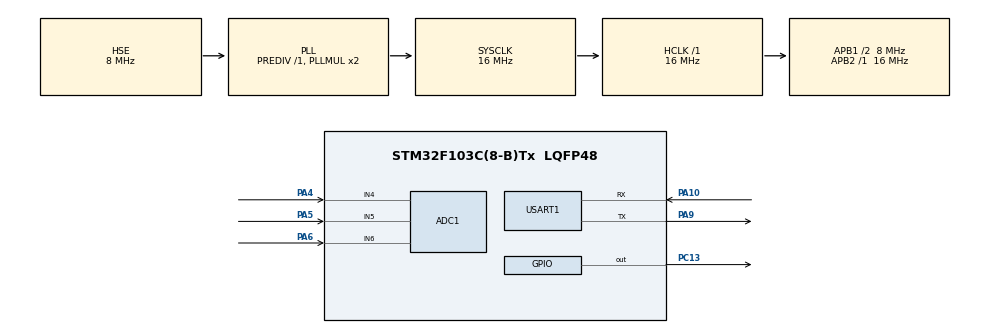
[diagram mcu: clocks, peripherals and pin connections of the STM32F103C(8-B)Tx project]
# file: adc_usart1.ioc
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ADC1.Channel-5\#ChannelRegularConversion=ADC_CHANNEL_4
ADC1.Channel-6\#ChannelRegularConversion=ADC_CHANNEL_5
ADC1.Channel-7\#ChannelRegularConversion=ADC_CHANNEL_6
ADC1.ContinuousConvMode=ENABLE
ADC1.NbrOfConversion=3
ADC1.NbrOfConversionFlag=1
ADC1.Rank-5\#ChannelRegularConversion=1
ADC1.Rank-6\#ChannelRegularConversion=2
ADC1.Rank-7\#ChannelRegularConversion=3
ADC1.SamplingTime-5\#ChannelRegularConversion=ADC_SAMPLETIME_239CYCLES_5
ADC1.SamplingTime-6\#ChannelRegularConversion=ADC_SAMPLETIME_239CYCLES_5
ADC1.SamplingTime-7\#ChannelRegularConversion=ADC_SAMPLETIME_239CYCLES_5
ADC1.master=1
Dma.ADC1.0.Direction=DMA_PERIPH_TO_MEMORY
Dma.ADC1.0.Instance=DMA1_Channel1
Dma.ADC1.0.MemDataAlignment=DMA_MDATAALIGN_WORD
Dma.ADC1.0.MemInc=DMA_MINC_ENABLE
Dma.ADC1.0.Mode=DMA_CIRCULAR
Dma.ADC1.0.PeriphDataAlignment=DMA_PDATAALIGN_WORD
Dma.ADC1.0.PeriphInc=DMA_PINC_DISABLE
Dma.ADC1.0.Priority=DMA_PRIORITY_LOW
Dma.Request0=ADC1
Mcu.Family=STM32F1
Mcu.Name=STM32F103C(8-B)Tx
Mcu.Package=LQFP48
NVIC.DMA1_Channel1_IRQn=true\:0\:0\:false\:false\:true\:false\:true
NVIC.PriorityGroup=NVIC_PRIORITYGROUP_4
PA10.Mode=Asynchronous
PA10.Signal=USART1_RX
PA13.Mode=Serial_Wire
PA13.Signal=SYS_JTMS-SWDIO
PA14.Mode=Serial_Wire
PA14.Signal=SYS_JTCK-SWCLK
PA4.Signal=ADCx_IN4
PA5.Signal=ADCx_IN5
PA6.Signal=ADCx_IN6
PA9.Mode=Asynchronous
PA9.Signal=USART1_TX
PC13-TAMPER-RTC.Signal=GPIO_Output
PD0-OSC_IN.Mode=HSE-External-Oscillator
PD0-OSC_IN.Signal=RCC_OSC_IN
PD1-OSC_OUT.Mode=HSE-External-Oscillator
PD1-OSC_OUT.Signal=RCC_OSC_OUT
ProjectManager.HeapSize=0x200
ProjectManager.StackSize=0x400
ProjectManager.TargetToolchain=STM32CubeIDE
RCC.AHBFreq_Value=16000000
RCC.APB1CLKDivider=RCC_HCLK_DIV2
RCC.APB1Freq_Value=8000000
RCC.APB1TimFreq_Value=16000000
RCC.APB2Freq_Value=16000000
RCC.APB2TimFreq_Value=16000000
RCC.HCLKFreq_Value=16000000
RCC.PLLSourceVirtual=RCC_PLLSOURCE_HSE
RCC.SYSCLKFreq_VALUE=16000000
RCC.SYSCLKSource=RCC_SYSCLKSOURCE_PLLCLK
RCC.USBFreq_Value=16000000
SH.ADCx_IN4.0=ADC1_IN4,IN4
SH.ADCx_IN5.0=ADC1_IN5,IN5
SH.ADCx_IN6.0=ADC1_IN6,IN6
USART1.VirtualMode=VM_ASYNC
board=custom

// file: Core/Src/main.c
/* USER CODE BEGIN Header */
/**
  ******************************************************************************
  * @file           : main.c
  * @brief          : Main program body
  ******************************************************************************
  * @attention
  *
  * <h2><center>&copy; Copyright (c) 2020 STMicroelectronics.
  * All rights reserved.</center></h2>
  *
  * This software component is licensed by ST under BSD 3-Clause license,
  * the "License"; You may not use this file except in compliance with the
  * License. You may obtain a copy of the License at:
  *                        opensource.org/licenses/BSD-3-Clause
  *
  ******************************************************************************
  */
/* USER CODE END Header */

#include "main.h"

/* USER CODE BEGIN Includes */
#include "stdio.h"
/* USER CODE END Includes */

ADC_HandleTypeDef hadc1;
DMA_HandleTypeDef hdma_adc1;

UART_HandleTypeDef huart1;

void SystemClock_Config(void);
static void MX_GPIO_Init(void);
static void MX_DMA_Init(void);
static void MX_ADC1_Init(void);
static void MX_USART1_UART_Init(void);
/* USER CODE BEGIN PFP */
uint32_t value[3];  // to store the adc values
char buffer[16];
//extern void initialise_monitor_handles(void);  monitor arm semihosting enable
/* USER CODE END PFP */

/* USER CODE BEGIN 0 */
/*int _write(int file , char *ptr, int len)
{
	int i =0;
	for (i=0;i<len;i++)
	{
		ITM_SendChar((*ptr++));

	}
	return len;

}
uint8_t count = 0 ;*/
/* USER CODE END 0 */

int main(void)
{

  /* MCU Configuration--------------------------------------------------------*/

  /* Reset of all peripherals, Initializes the Flash interface and the Systick. */
  HAL_Init();

  /* Configure the system clock */
  SystemClock_Config();

  /* Initialize all configured peripherals */
  MX_GPIO_Init();
  MX_DMA_Init();
  MX_ADC1_Init();
  MX_USART1_UART_Init();
  /* USER CODE BEGIN 2 */
  HAL_ADC_Start_DMA(&hadc1, value, 3);  // start the adc in dma mode
//  initialise_monitor_handles();
  /* USER CODE END 2 */

  /* Infinite loop */
  while (1)
  {

    /* USER CODE BEGIN 3 */
	  HAL_UART_Transmit(&huart1, (uint8_t*)buffer, sprintf(buffer, "%ld ",        value[0]), 500);
	  HAL_Delay (10); // 200ms delay
	  HAL_UART_Transmit(&huart1, (uint8_t*)buffer, sprintf(buffer, "%ld ",        value[1]), 500);
	  HAL_Delay (10); // 200ms delay
	  HAL_UART_Transmit(&huart1, (uint8_t*)buffer, sprintf(buffer, "%ld \n", value[2]), 500);
	  HAL_Delay (10); // 200ms delay
      HAL_GPIO_TogglePin(GPIOC, GPIO_PIN_13);
      HAL_Delay (10); // 200ms delay
     // printf("adc 0 =  %ld  %ld  %ld \n", value[0] , value[1] ,value[2]);
     //printf("adc 1 =  %ld \n", value[1]);
     //printf("adc 2 =  %ld \n", value[2]);
  }
  /* USER CODE END 3 */
}

void SystemClock_Config(void)
{
  RCC_OscInitTypeDef RCC_OscInitStruct = {0};
  RCC_ClkInitTypeDef RCC_ClkInitStruct = {0};
  RCC_PeriphCLKInitTypeDef PeriphClkInit = {0};

  /** Initializes the CPU, AHB and APB busses clocks
  */
  RCC_OscInitStruct.OscillatorType = RCC_OSCILLATORTYPE_HSE;
  RCC_OscInitStruct.HSEState = RCC_HSE_ON;
  RCC_OscInitStruct.HSEPredivValue = RCC_HSE_PREDIV_DIV1;
  RCC_OscInitStruct.HSIState = RCC_HSI_ON;
  RCC_OscInitStruct.PLL.PLLState = RCC_PLL_ON;
  RCC_OscInitStruct.PLL.PLLSource = RCC_PLLSOURCE_HSE;
  RCC_OscInitStruct.PLL.PLLMUL = RCC_PLL_MUL2;
  if (HAL_RCC_OscConfig(&RCC_OscInitStruct) != HAL_OK)
  {
    Error_Handler();
  }
  /** Initializes the CPU, AHB and APB busses clocks
  */
  RCC_ClkInitStruct.ClockType = RCC_CLOCKTYPE_HCLK|RCC_CLOCKTYPE_SYSCLK
                              |RCC_CLOCKTYPE_PCLK1|RCC_CLOCKTYPE_PCLK2;
  RCC_ClkInitStruct.SYSCLKSource = RCC_SYSCLKSOURCE_PLLCLK;
  RCC_ClkInitStruct.AHBCLKDivider = RCC_SYSCLK_DIV1;
  RCC_ClkInitStruct.APB1CLKDivider = RCC_HCLK_DIV2;
  RCC_ClkInitStruct.APB2CLKDivider = RCC_HCLK_DIV1;

  if (HAL_RCC_ClockConfig(&RCC_ClkInitStruct, FLASH_LATENCY_0) != HAL_OK)
  {
    Error_Handler();
  }
  PeriphClkInit.PeriphClockSelection = RCC_PERIPHCLK_ADC;
  PeriphClkInit.AdcClockSelection = RCC_ADCPCLK2_DIV2;
  if (HAL_RCCEx_PeriphCLKConfig(&PeriphClkInit) != HAL_OK)
  {
    Error_Handler();
  }
}

static void MX_ADC1_Init(void)
{

  ADC_ChannelConfTypeDef sConfig = {0};

  /** Common config
  */
  hadc1.Instance = ADC1;
  hadc1.Init.ScanConvMode = ADC_SCAN_ENABLE;
  hadc1.Init.ContinuousConvMode = ENABLE;
  hadc1.Init.DiscontinuousConvMode = DISABLE;
  hadc1.Init.ExternalTrigConv = ADC_SOFTWARE_START;
  hadc1.Init.DataAlign = ADC_DATAALIGN_RIGHT;
  hadc1.Init.NbrOfConversion = 3;
  if (HAL_ADC_Init(&hadc1) != HAL_OK)
  {
    Error_Handler();
  }
  /** Configure Regular Channel
  */
  sConfig.Channel = ADC_CHANNEL_4;
  sConfig.Rank = ADC_REGULAR_RANK_1;
  sConfig.SamplingTime = ADC_SAMPLETIME_239CYCLES_5;
  if (HAL_ADC_ConfigChannel(&hadc1, &sConfig) != HAL_OK)
  {
    Error_Handler();
  }
  /** Configure Regular Channel
  */
  sConfig.Channel = ADC_CHANNEL_5;
  sConfig.Rank = ADC_REGULAR_RANK_2;
  if (HAL_ADC_ConfigChannel(&hadc1, &sConfig) != HAL_OK)
  {
    Error_Handler();
  }
  /** Configure Regular Channel
  */
  sConfig.Channel = ADC_CHANNEL_6;
  sConfig.Rank = ADC_REGULAR_RANK_3;
  if (HAL_ADC_ConfigChannel(&hadc1, &sConfig) != HAL_OK)
  {
    Error_Handler();
  }

}

static void MX_USART1_UART_Init(void)
{

  huart1.Instance = USART1;
  huart1.Init.BaudRate = 115200;
  huart1.Init.WordLength = UART_WORDLENGTH_8B;
  huart1.Init.StopBits = UART_STOPBITS_1;
  huart1.Init.Parity = UART_PARITY_NONE;
  huart1.Init.Mode = UART_MODE_TX_RX;
  huart1.Init.HwFlowCtl = UART_HWCONTROL_NONE;
  huart1.Init.OverSampling = UART_OVERSAMPLING_16;
  if (HAL_UART_Init(&huart1) != HAL_OK)
  {
    Error_Handler();
  }

}

static void MX_DMA_Init(void)
{

  /* DMA controller clock enable */
  __HAL_RCC_DMA1_CLK_ENABLE();

  /* DMA interrupt init */
  /* DMA1_Channel1_IRQn interrupt configuration */
  HAL_NVIC_SetPriority(DMA1_Channel1_IRQn, 0, 0);
  HAL_NVIC_EnableIRQ(DMA1_Channel1_IRQn);

}

static void MX_GPIO_Init(void)
{
  GPIO_InitTypeDef GPIO_InitStruct = {0};

  /* GPIO Ports Clock Enable */
  __HAL_RCC_GPIOC_CLK_ENABLE();
  __HAL_RCC_GPIOD_CLK_ENABLE();
  __HAL_RCC_GPIOA_CLK_ENABLE();

  /*Configure GPIO pin Output Level */
  HAL_GPIO_WritePin(GPIOC, GPIO_PIN_13, GPIO_PIN_RESET);

  /*Configure GPIO pin : PC13 */
  GPIO_InitStruct.Pin = GPIO_PIN_13;
  GPIO_InitStruct.Mode = GPIO_MODE_OUTPUT_PP;
  GPIO_InitStruct.Pull = GPIO_NOPULL;
  GPIO_InitStruct.Speed = GPIO_SPEED_FREQ_LOW;
  HAL_GPIO_Init(GPIOC, &GPIO_InitStruct);

}

void Error_Handler(void)
{
}

/************************ (C) COPYRIGHT STMicroelectronics *****END OF FILE****/
